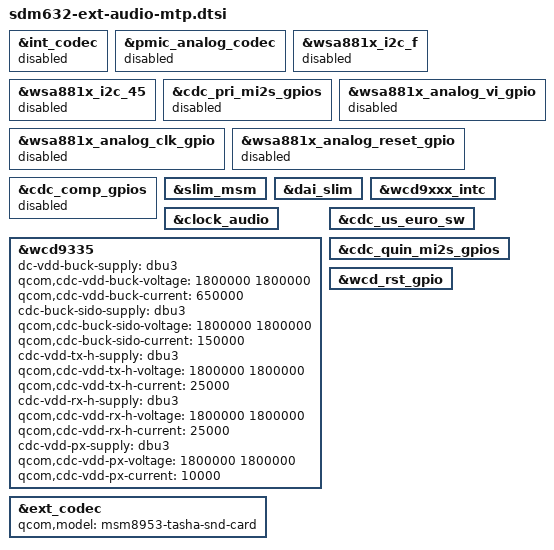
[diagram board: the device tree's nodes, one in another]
/*
 * Copyright (c) 2018, The Linux Foundation. All rights reserved.
 *
 * This program is free software; you can redistribute it and/or modify
 * it under the terms of the GNU General Public License version 2 and
 * only version 2 as published by the Free Software Foundation.
 *
 * This program is distributed in the hope that it will be useful,
 * but WITHOUT ANY WARRANTY; without even the implied warranty of
 * MERCHANTABILITY or FITNESS FOR A PARTICULAR PURPOSE.  See the
 * GNU General Public License for more details.
 */

&int_codec {
	status = "disabled";
};

&pmic_analog_codec {
	status = "disabled";
};

&wsa881x_i2c_f {
	status = "disabled";
};

&wsa881x_i2c_45 {
	status = "disabled";
};

&cdc_pri_mi2s_gpios {
	status = "disabled";
};

&wsa881x_analog_vi_gpio {
	status = "disabled";
};

&wsa881x_analog_clk_gpio {
	status = "disabled";
};

&wsa881x_analog_reset_gpio {
	status = "disabled";
};

&cdc_comp_gpios {
	status = "disabled";
};

&slim_msm {
	status = "okay";
};

&dai_slim {
	status = "okay";
};

&wcd9xxx_intc {
	status = "okay";
};

&clock_audio {
	status = "okay";
};

&wcd9335 {
	status = "okay";

	dc-vdd-buck-supply = <&dbu3>;
	qcom,cdc-vdd-buck-voltage = <1800000 1800000>;
	qcom,cdc-vdd-buck-current = <650000>;

	cdc-buck-sido-supply = <&dbu3>;
	qcom,cdc-buck-sido-voltage = <1800000 1800000>;
	qcom,cdc-buck-sido-current = <150000>;

	cdc-vdd-tx-h-supply = <&dbu3>;
	qcom,cdc-vdd-tx-h-voltage = <1800000 1800000>;
	qcom,cdc-vdd-tx-h-current = <25000>;

	cdc-vdd-rx-h-supply = <&dbu3>;
	qcom,cdc-vdd-rx-h-voltage = <1800000 1800000>;
	qcom,cdc-vdd-rx-h-current = <25000>;

	cdc-vdd-px-supply = <&dbu3>;
	qcom,cdc-vdd-px-voltage = <1800000 1800000>;
	qcom,cdc-vdd-px-current = <10000>;
};

&cdc_us_euro_sw {
	status = "okay";
};

&cdc_quin_mi2s_gpios {
	status = "okay";
};

&wcd_rst_gpio {
	status = "okay";
};

&ext_codec {
	qcom,model = "msm8953-tasha-snd-card";
	status = "okay";
};
